# STM32U595xx register map
File version: 1.0
Registers are 32-bit, read-write, reset 0x0 unless marked. A register's access mark holds for its fields unless they carry their own. Offsets are from the block's base; [hi:lo] are bit positions; {n}, {i} and the like mark numbered series; 'fields as' and 'values as' point back to an identical list.

## OCTOSPIM — Serial Peripheral Interface IO Manager
Base 0x420C4000
Same registers: OCTOSPIM_S 0x520C4000
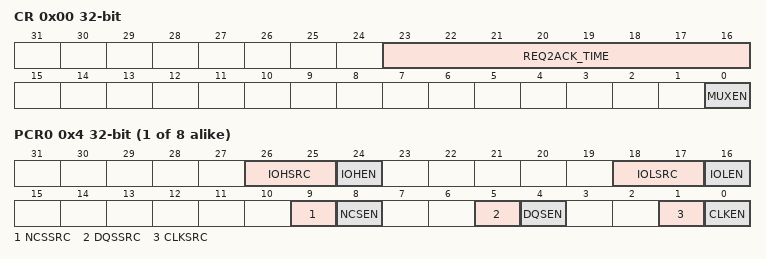
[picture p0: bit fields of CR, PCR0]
0x00 CR — OCTOSPIM IO Manager Control register
  [23:16] REQ2ACK_TIME — REQ to ACK Time
  [0] MUXEN — Multiplexed Mode Enable
{0x4+4i} PCR{i} (i=0..7) — OCTOSPIM IO Manager Port[1:8] Configuration register
  [26:25] IOHSRC — IO[7:4] Source for Port n
  [24] IOHEN — IO[7:4] Enable for Port n
  [18:17] IOLSRC — IO[3:0] Source for Port n
  [16] IOLEN — IO[3:0] Enable for Port n
  [9] NCSSRC — nCS Source for Port n
  [8] NCSEN — nCS Enable for Port n
  [5] DQSSRC — DQS Source for Port n
  [4] DQSEN — DQS Enable for Port n
  [1] CLKSRC — CLK/CLKn Source for Port n
  [0] CLKEN — CLK/CLKn Enable for Port n

## DLYB_SDMMC1 — Delay Block DLYB
Base 0x420C8400
Same registers: DLYB_SDMMC2 0x420C8800, DLYB_OCTOSPI1 0x420CF000, DLYB_OCTOSPI2 0x420CF400, DLYB_SDMMC1_S 0x520C8400, DLYB_SDMMC2_S 0x520C8800, DLYB_OCTOSPI1_S 0x520CF000, DLYB_OCTOSPI2_S 0x520CF400
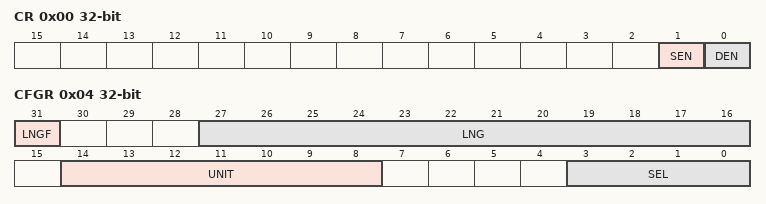
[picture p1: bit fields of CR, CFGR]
0x00 CR — DELAY BLOCK control register
  [1] SEN — Sampler length enable
  [0] DEN — Delay Block enable
0x04 CFGR — DELAY BLOCK configuration register
  [31] LNGF — Length valid flag
  [27:16] LNG — Delay line length value[11:0]
  [14:8] UNIT — Delay Defines the delay of a Unit delay cell[6:0]
  [3:0] SEL — Select the phase for the Output clock[3:0]

## FMC_Bank1_R — Flexible Memory Controller
Base 0x420D0400
Same registers: FMC_Bank1_R_S 0x520D0400
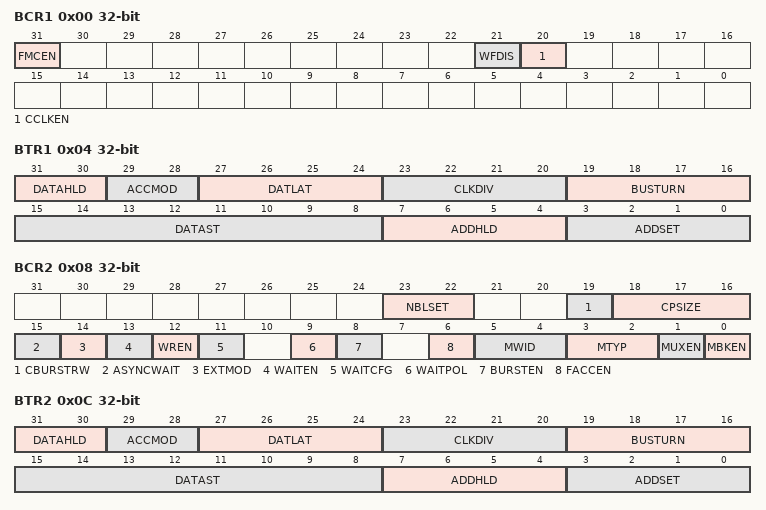
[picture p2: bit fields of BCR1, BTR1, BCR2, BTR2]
0x00 BCR1 — NOR/PSRAM chip-select control register(BCR) and chip-select timing register(BTR)
  [31] FMCEN — FMC controller Enable
  [21] WFDIS — Write FIFO Disable
  [20] CCLKEN — Continuous clock enable
0x04 BTR1 — NOR/PSRAM chip-select control register(BCR) and chip-select timing register(BTR)
  [31:30] DATAHLD — DATAHLD[1:0] bits (Data hold phase duration)
  [29:28] ACCMOD — ACCMOD[1:0] bits (Access mode)
  [27:24] DATLAT — DATLA[3:0] bits (Data latency)
  [23:20] CLKDIV — CLKDIV[3:0] bits (Clock divide ratio)
  [19:16] BUSTURN — BUSTURN[3:0] bits (Bus turnaround phase duration)
  [15:8] DATAST — DATAST [3:0] bits (Data-phase duration)
  [7:4] ADDHLD — ADDHLD[3:0] bits (Address-hold phase duration)
  [3:0] ADDSET — ADDSET[3:0] bits (Address setup phase duration)
0x08 BCR2 — NOR/PSRAM chip-select control register(BCR) and chip-select timing register(BTR)
  [23:22] NBLSET — Byte lane (NBL) setup
  [19] CBURSTRW — Write burst enable
  [18:16] CPSIZE — PSIZE[2:0] bits CRAM Page Size
  [15] ASYNCWAIT — Asynchronous wait
  [14] EXTMOD — Extended mode enable
  [13] WAITEN — Wait enable bit
  [12] WREN — Write enable bit
  [11] WAITCFG — Wait timing configuration
  [9] WAITPOL — Wait signal polarity bit
  [8] BURSTEN — Burst enable bit
  [6] FACCEN — Flash access enable
  [5:4] MWID — MWID[1:0] bits (Memory data bus width)
  [3:2] MTYP — MTYP[1:0] bits (Memory type)
  [1] MUXEN — Address/data multiplexing enable bit
  [0] MBKEN — Memory bank enable bit
0x0C BTR2 — NOR/PSRAM chip-select control register(BCR) and chip-select timing register(BTR)
  fields as BTR1
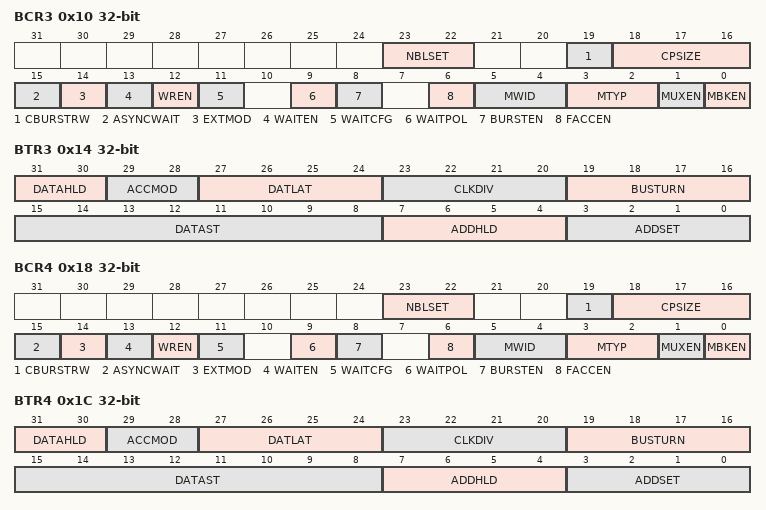
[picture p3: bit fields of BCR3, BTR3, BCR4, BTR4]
0x10 BCR3 — NOR/PSRAM chip-select control register(BCR) and chip-select timing register(BTR)
  fields as BCR2
0x14 BTR3 — NOR/PSRAM chip-select control register(BCR) and chip-select timing register(BTR)
  fields as BTR1
0x18 BCR4 — NOR/PSRAM chip-select control register(BCR) and chip-select timing register(BTR)
  fields as BCR2
0x1C BTR4 — NOR/PSRAM chip-select control register(BCR) and chip-select timing register(BTR)
  fields as BTR1
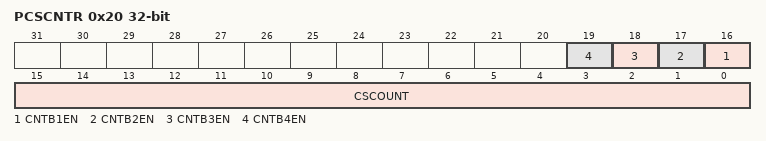
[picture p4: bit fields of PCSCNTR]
0x20 PCSCNTR — PSRAM chip-select counter register
  [n+15] CNTB{n}EN (n=1..4) — Counter PSRAM/NOR Bank1_{n} enable
  [15:0] CSCOUNT — CSCOUNT[15:0] bits (Chip select counter)

## FMC_Bank3_R — Flexible Memory Controller Bank3
Base 0x420D0480
Same registers: FMC_Bank3_R_S 0x520D0480
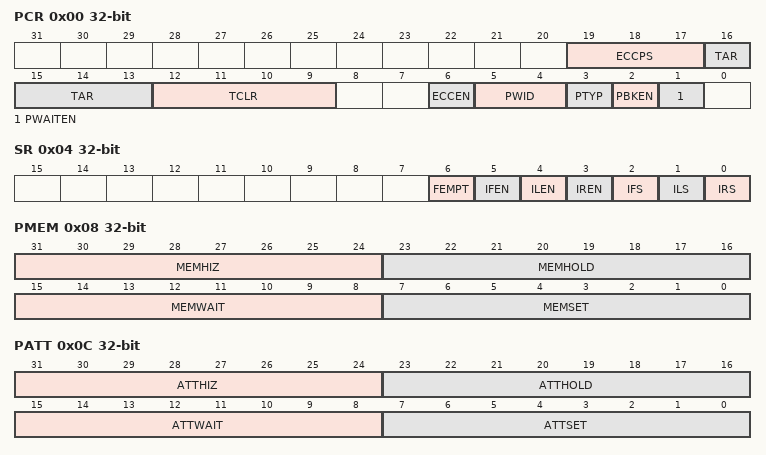
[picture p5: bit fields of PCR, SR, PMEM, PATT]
0x00 PCR — NAND Flash control register
  [19:17] ECCPS — ECCPS[1:0] bits (ECC page size)
  [16:13] TAR — TAR[3:0] bits (ALE to RE delay)
  [12:9] TCLR — TCLR[3:0] bits (CLE to RE delay)
  [6] ECCEN — ECC computation logic enable bit
  [5:4] PWID — PWID[1:0] bits (NAND Flash databus width)
  [3] PTYP — Memory type
  [2] PBKEN — NAND Flash memory bank enable bit
  [1] PWAITEN — Wait feature enable bit
0x04 SR — NAND Flash FIFO status and interrupt register
  [6] FEMPT — FIFO empty
  [5] IFEN — Interrupt Falling Edge detection Enable bit
  [4] ILEN — Interrupt Level detection Enable bit
  [3] IREN — Interrupt Rising Edge detection Enable bit
  [2] IFS — Interrupt Falling Edge status
  [1] ILS — Interrupt Level status
  [0] IRS — Interrupt Rising Edge status
0x08 PMEM — NAND Flash Common memory space timing register
  [31:24] MEMHIZ — MEMHIZ[7:0] bits (Common memory databus HiZ time)
  [23:16] MEMHOLD — MEMHOLD[7:0] bits (Common memory hold time)
  [15:8] MEMWAIT — MEMWAIT[7:0] bits (Common memory wait time)
  [7:0] MEMSET — MEMSET[7:0] bits (Common memory setup time)
0x0C PATT — NAND Flash Attribute memory space timing register
  [31:24] ATTHIZ — ATTHIZ[7:0] bits (Attribute memory databus HiZ time)
  [23:16] ATTHOLD — ATTHOLD[7:0] bits (Attribute memory hold time)
  [15:8] ATTWAIT — ATTWAIT[7:0] bits (Attribute memory wait time)
  [7:0] ATTSET — ATTSET[7:0] bits (Attribute memory setup time)
0x14 ECCR — NAND Flash ECC result registers
